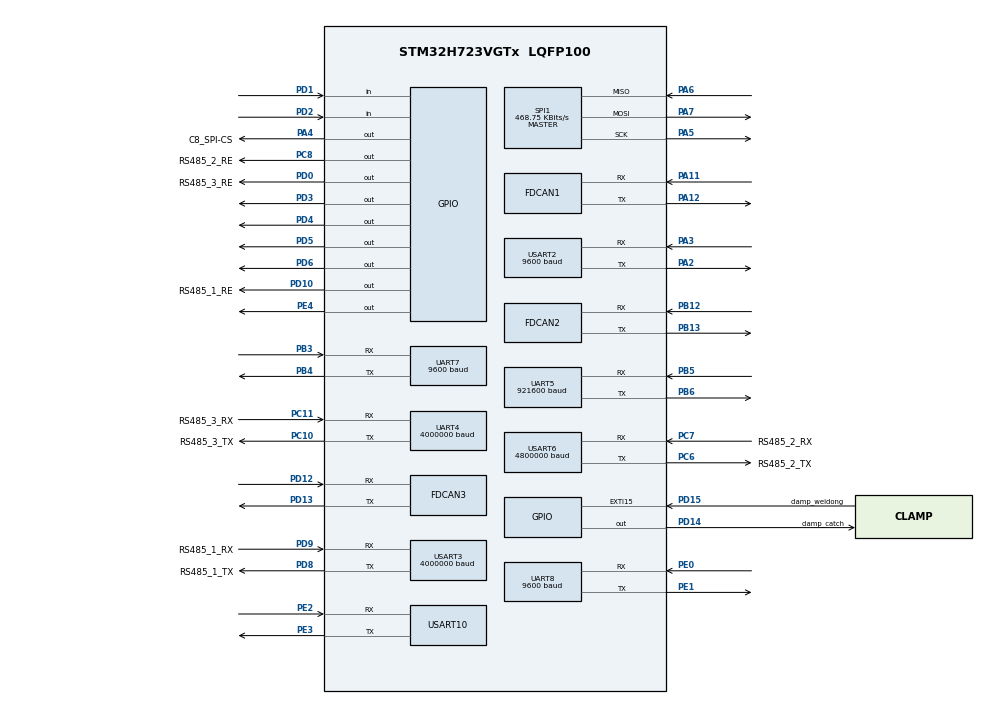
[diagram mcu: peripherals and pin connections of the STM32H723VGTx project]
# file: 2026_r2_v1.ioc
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CORTEX_M7.default_mode_Activation=1
Dma.Request0=UART5_RX
Dma.Request1=UART5_TX
Dma.Request10=USART10_RX
Dma.Request11=USART10_TX
Dma.Request12=UART8_RX
Dma.Request13=UART8_TX
Dma.Request14=USART2_TX
Dma.Request15=USART2_RX
Dma.Request2=USART3_TX
Dma.Request3=USART3_RX
Dma.Request4=USART6_TX
Dma.Request5=USART6_RX
Dma.Request6=UART4_TX
Dma.Request7=UART4_RX
Dma.Request8=UART7_TX
Dma.Request9=UART7_RX
Dma.UART4_RX.7.Direction=DMA_PERIPH_TO_MEMORY
Dma.UART4_RX.7.EventEnable=DISABLE
Dma.UART4_RX.7.FIFOMode=DMA_FIFOMODE_DISABLE
Dma.UART4_RX.7.Instance=DMA1_Stream5
Dma.UART4_RX.7.MemDataAlignment=DMA_MDATAALIGN_BYTE
Dma.UART4_RX.7.MemInc=DMA_MINC_ENABLE
Dma.UART4_RX.7.Mode=DMA_NORMAL
Dma.UART4_RX.7.PeriphDataAlignment=DMA_PDATAALIGN_BYTE
Dma.UART4_RX.7.PeriphInc=DMA_PINC_DISABLE
Dma.UART4_RX.7.Polarity=HAL_DMAMUX_REQ_GEN_RISING
Dma.UART4_RX.7.Priority=DMA_PRIORITY_LOW
Dma.UART4_RX.7.RequestNumber=1
Dma.UART4_RX.7.SignalID=NONE
Dma.UART4_RX.7.SyncEnable=DISABLE
Dma.UART4_RX.7.SyncPolarity=HAL_DMAMUX_SYNC_NO_EVENT
Dma.UART4_RX.7.SyncRequestNumber=1
Dma.UART4_RX.7.SyncSignalID=NONE
Dma.UART4_TX.6.Direction=DMA_MEMORY_TO_PERIPH
Dma.UART4_TX.6.EventEnable=DISABLE
Dma.UART4_TX.6.FIFOMode=DMA_FIFOMODE_DISABLE
Dma.UART4_TX.6.Instance=DMA1_Stream4
Dma.UART4_TX.6.MemDataAlignment=DMA_MDATAALIGN_BYTE
Dma.UART4_TX.6.MemInc=DMA_MINC_ENABLE
Dma.UART4_TX.6.Mode=DMA_NORMAL
Dma.UART4_TX.6.PeriphDataAlignment=DMA_PDATAALIGN_BYTE
Dma.UART4_TX.6.PeriphInc=DMA_PINC_DISABLE
Dma.UART4_TX.6.Polarity=HAL_DMAMUX_REQ_GEN_RISING
Dma.UART4_TX.6.Priority=DMA_PRIORITY_LOW
Dma.UART4_TX.6.RequestNumber=1
Dma.UART4_TX.6.SignalID=NONE
Dma.UART4_TX.6.SyncEnable=DISABLE
Dma.UART4_TX.6.SyncPolarity=HAL_DMAMUX_SYNC_NO_EVENT
Dma.UART4_TX.6.SyncRequestNumber=1
Dma.UART4_TX.6.SyncSignalID=NONE
Dma.UART5_RX.0.Direction=DMA_PERIPH_TO_MEMORY
Dma.UART5_RX.0.EventEnable=DISABLE
Dma.UART5_RX.0.FIFOMode=DMA_FIFOMODE_DISABLE
Dma.UART5_RX.0.Instance=DMA2_Stream2
Dma.UART5_RX.0.MemDataAlignment=DMA_MDATAALIGN_BYTE
Dma.UART5_RX.0.MemInc=DMA_MINC_ENABLE
Dma.UART5_RX.0.Mode=DMA_NORMAL
Dma.UART5_RX.0.PeriphDataAlignment=DMA_PDATAALIGN_BYTE
Dma.UART5_RX.0.PeriphInc=DMA_PINC_DISABLE
Dma.UART5_RX.0.Polarity=HAL_DMAMUX_REQ_GEN_RISING
Dma.UART5_RX.0.Priority=DMA_PRIORITY_LOW
Dma.UART5_RX.0.RequestNumber=1
Dma.UART5_RX.0.SignalID=NONE
Dma.UART5_RX.0.SyncEnable=DISABLE
Dma.UART5_RX.0.SyncPolarity=HAL_DMAMUX_SYNC_NO_EVENT
Dma.UART5_RX.0.SyncRequestNumber=1
Dma.UART5_RX.0.SyncSignalID=NONE
Dma.UART5_TX.1.Direction=DMA_MEMORY_TO_PERIPH
Dma.UART5_TX.1.EventEnable=DISABLE
Dma.UART5_TX.1.FIFOMode=DMA_FIFOMODE_DISABLE
Dma.UART5_TX.1.Instance=DMA2_Stream3
Dma.UART5_TX.1.MemDataAlignment=DMA_MDATAALIGN_BYTE
Dma.UART5_TX.1.MemInc=DMA_MINC_ENABLE
Dma.UART5_TX.1.Mode=DMA_NORMAL
Dma.UART5_TX.1.PeriphDataAlignment=DMA_PDATAALIGN_BYTE
Dma.UART5_TX.1.PeriphInc=DMA_PINC_DISABLE
Dma.UART5_TX.1.Polarity=HAL_DMAMUX_REQ_GEN_RISING
Dma.UART5_TX.1.Priority=DMA_PRIORITY_LOW
Dma.UART5_TX.1.RequestNumber=1
Dma.UART5_TX.1.SignalID=NONE
Dma.UART5_TX.1.SyncEnable=DISABLE
Dma.UART5_TX.1.SyncPolarity=HAL_DMAMUX_SYNC_NO_EVENT
Dma.UART5_TX.1.SyncRequestNumber=1
Dma.UART5_TX.1.SyncSignalID=NONE
Dma.UART7_RX.9.Direction=DMA_PERIPH_TO_MEMORY
Dma.UART7_RX.9.EventEnable=DISABLE
Dma.UART7_RX.9.FIFOMode=DMA_FIFOMODE_DISABLE
Dma.UART7_RX.9.Instance=DMA1_Stream7
Dma.UART7_RX.9.MemDataAlignment=DMA_MDATAALIGN_BYTE
Dma.UART7_RX.9.MemInc=DMA_MINC_ENABLE
Dma.UART7_RX.9.Mode=DMA_NORMAL
Dma.UART7_RX.9.PeriphDataAlignment=DMA_PDATAALIGN_BYTE
Dma.UART7_RX.9.PeriphInc=DMA_PINC_DISABLE
Dma.UART7_RX.9.Polarity=HAL_DMAMUX_REQ_GEN_RISING
Dma.UART7_RX.9.Priority=DMA_PRIORITY_LOW
Dma.UART7_RX.9.RequestNumber=1
Dma.UART7_RX.9.SignalID=NONE
Dma.UART7_RX.9.SyncEnable=DISABLE
Dma.UART7_RX.9.SyncPolarity=HAL_DMAMUX_SYNC_NO_EVENT
Dma.UART7_RX.9.SyncRequestNumber=1
Dma.UART7_RX.9.SyncSignalID=NONE
Dma.UART7_TX.8.Direction=DMA_MEMORY_TO_PERIPH
Dma.UART7_TX.8.EventEnable=DISABLE
Dma.UART7_TX.8.FIFOMode=DMA_FIFOMODE_DISABLE
Dma.UART7_TX.8.Instance=DMA1_Stream6
Dma.UART7_TX.8.MemDataAlignment=DMA_MDATAALIGN_BYTE
Dma.UART7_TX.8.MemInc=DMA_MINC_ENABLE
Dma.UART7_TX.8.Mode=DMA_NORMAL
Dma.UART7_TX.8.PeriphDataAlignment=DMA_PDATAALIGN_BYTE
Dma.UART7_TX.8.PeriphInc=DMA_PINC_DISABLE
Dma.UART7_TX.8.Polarity=HAL_DMAMUX_REQ_GEN_RISING
Dma.UART7_TX.8.Priority=DMA_PRIORITY_LOW
Dma.UART7_TX.8.RequestNumber=1
Dma.UART7_TX.8.SignalID=NONE
Dma.UART7_TX.8.SyncEnable=DISABLE
Dma.UART7_TX.8.SyncPolarity=HAL_DMAMUX_SYNC_NO_EVENT
Dma.UART7_TX.8.SyncRequestNumber=1
Dma.UART7_TX.8.SyncSignalID=NONE
Dma.UART8_RX.12.Direction=DMA_PERIPH_TO_MEMORY
Dma.UART8_RX.12.EventEnable=DISABLE
Dma.UART8_RX.12.FIFOMode=DMA_FIFOMODE_DISABLE
Dma.UART8_RX.12.Instance=DMA2_Stream4
Dma.UART8_RX.12.MemDataAlignment=DMA_MDATAALIGN_BYTE
Dma.UART8_RX.12.MemInc=DMA_MINC_ENABLE
Dma.UART8_RX.12.Mode=DMA_NORMAL
Dma.UART8_RX.12.PeriphDataAlignment=DMA_PDATAALIGN_BYTE
Dma.UART8_RX.12.PeriphInc=DMA_PINC_DISABLE
Dma.UART8_RX.12.Polarity=HAL_DMAMUX_REQ_GEN_RISING
Dma.UART8_RX.12.Priority=DMA_PRIORITY_LOW
Dma.UART8_RX.12.RequestNumber=1
Dma.UART8_RX.12.SignalID=NONE
Dma.UART8_RX.12.SyncEnable=DISABLE
Dma.UART8_RX.12.SyncPolarity=HAL_DMAMUX_SYNC_NO_EVENT
Dma.UART8_RX.12.SyncRequestNumber=1
Dma.UART8_RX.12.SyncSignalID=NONE
Dma.UART8_TX.13.Direction=DMA_MEMORY_TO_PERIPH
Dma.UART8_TX.13.EventEnable=DISABLE
Dma.UART8_TX.13.FIFOMode=DMA_FIFOMODE_DISABLE
Dma.UART8_TX.13.Instance=DMA2_Stream5
Dma.UART8_TX.13.MemDataAlignment=DMA_MDATAALIGN_BYTE
Dma.UART8_TX.13.MemInc=DMA_MINC_ENABLE
Dma.UART8_TX.13.Mode=DMA_NORMAL
Dma.UART8_TX.13.PeriphDataAlignment=DMA_PDATAALIGN_BYTE
Dma.UART8_TX.13.PeriphInc=DMA_PINC_DISABLE
Dma.UART8_TX.13.Polarity=HAL_DMAMUX_REQ_GEN_RISING
Dma.UART8_TX.13.Priority=DMA_PRIORITY_LOW
Dma.UART8_TX.13.RequestNumber=1
Dma.UART8_TX.13.SignalID=NONE
Dma.UART8_TX.13.SyncEnable=DISABLE
Dma.UART8_TX.13.SyncPolarity=HAL_DMAMUX_SYNC_NO_EVENT
Dma.UART8_TX.13.SyncRequestNumber=1
Dma.UART8_TX.13.SyncSignalID=NONE
Dma.USART10_RX.10.Direction=DMA_PERIPH_TO_MEMORY
Dma.USART10_RX.10.EventEnable=DISABLE
Dma.USART10_RX.10.FIFOMode=DMA_FIFOMODE_DISABLE
Dma.USART10_RX.10.Instance=DMA2_Stream0
Dma.USART10_RX.10.MemDataAlignment=DMA_MDATAALIGN_BYTE
Dma.USART10_RX.10.MemInc=DMA_MINC_ENABLE
Dma.USART10_RX.10.Mode=DMA_NORMAL
Dma.USART10_RX.10.PeriphDataAlignment=DMA_PDATAALIGN_BYTE
Dma.USART10_RX.10.PeriphInc=DMA_PINC_DISABLE
Dma.USART10_RX.10.Polarity=HAL_DMAMUX_REQ_GEN_RISING
Dma.USART10_RX.10.Priority=DMA_PRIORITY_LOW
Dma.USART10_RX.10.RequestNumber=1
Dma.USART10_RX.10.SignalID=NONE
Dma.USART10_RX.10.SyncEnable=DISABLE
Dma.USART10_RX.10.SyncPolarity=HAL_DMAMUX_SYNC_NO_EVENT
Dma.USART10_RX.10.SyncRequestNumber=1
Dma.USART10_RX.10.SyncSignalID=NONE
Dma.USART10_TX.11.Direction=DMA_MEMORY_TO_PERIPH
Dma.USART10_TX.11.EventEnable=DISABLE
Dma.USART10_TX.11.FIFOMode=DMA_FIFOMODE_DISABLE
Dma.USART10_TX.11.Instance=DMA2_Stream1
Dma.USART10_TX.11.MemDataAlignment=DMA_MDATAALIGN_BYTE
Dma.USART10_TX.11.MemInc=DMA_MINC_ENABLE
Dma.USART10_TX.11.Mode=DMA_NORMAL
Dma.USART10_TX.11.PeriphDataAlignment=DMA_PDATAALIGN_BYTE
Dma.USART10_TX.11.PeriphInc=DMA_PINC_DISABLE
Dma.USART10_TX.11.Polarity=HAL_DMAMUX_REQ_GEN_RISING
Dma.USART10_TX.11.Priority=DMA_PRIORITY_LOW
Dma.USART10_TX.11.RequestNumber=1
Dma.USART10_TX.11.SignalID=NONE
Dma.USART10_TX.11.SyncEnable=DISABLE
Dma.USART10_TX.11.SyncPolarity=HAL_DMAMUX_SYNC_NO_EVENT
Dma.USART10_TX.11.SyncRequestNumber=1
Dma.USART10_TX.11.SyncSignalID=NONE
Dma.USART2_RX.15.Direction=DMA_PERIPH_TO_MEMORY
Dma.USART2_RX.15.EventEnable=DISABLE
Dma.USART2_RX.15.FIFOMode=DMA_FIFOMODE_DISABLE
Dma.USART2_RX.15.Instance=DMA2_Stream7
Dma.USART2_RX.15.MemDataAlignment=DMA_MDATAALIGN_BYTE
Dma.USART2_RX.15.MemInc=DMA_MINC_ENABLE
Dma.USART2_RX.15.Mode=DMA_NORMAL
Dma.USART2_RX.15.PeriphDataAlignment=DMA_PDATAALIGN_BYTE
Dma.USART2_RX.15.PeriphInc=DMA_PINC_DISABLE
Dma.USART2_RX.15.Polarity=HAL_DMAMUX_REQ_GEN_RISING
Dma.USART2_RX.15.Priority=DMA_PRIORITY_LOW
Dma.USART2_RX.15.RequestNumber=1
Dma.USART2_RX.15.SignalID=NONE
Dma.USART2_RX.15.SyncEnable=DISABLE
Dma.USART2_RX.15.SyncPolarity=HAL_DMAMUX_SYNC_NO_EVENT
Dma.USART2_RX.15.SyncRequestNumber=1
Dma.USART2_RX.15.SyncSignalID=NONE
Dma.USART2_TX.14.Direction=DMA_MEMORY_TO_PERIPH
Dma.USART2_TX.14.EventEnable=DISABLE
Dma.USART2_TX.14.FIFOMode=DMA_FIFOMODE_DISABLE
Dma.USART2_TX.14.Instance=DMA2_Stream6
Dma.USART2_TX.14.MemDataAlignment=DMA_MDATAALIGN_BYTE
Dma.USART2_TX.14.MemInc=DMA_MINC_ENABLE
Dma.USART2_TX.14.Mode=DMA_NORMAL
Dma.USART2_TX.14.PeriphDataAlignment=DMA_PDATAALIGN_BYTE
Dma.USART2_TX.14.PeriphInc=DMA_PINC_DISABLE
Dma.USART2_TX.14.Polarity=HAL_DMAMUX_REQ_GEN_RISING
Dma.USART2_TX.14.Priority=DMA_PRIORITY_LOW
Dma.USART2_TX.14.RequestNumber=1
Dma.USART2_TX.14.SignalID=NONE
Dma.USART2_TX.14.SyncEnable=DISABLE
Dma.USART2_TX.14.SyncPolarity=HAL_DMAMUX_SYNC_NO_EVENT
Dma.USART2_TX.14.SyncRequestNumber=1
Dma.USART2_TX.14.SyncSignalID=NONE
Dma.USART3_RX.3.Direction=DMA_PERIPH_TO_MEMORY
Dma.USART3_RX.3.EventEnable=DISABLE
Dma.USART3_RX.3.FIFOMode=DMA_FIFOMODE_DISABLE
Dma.USART3_RX.3.Instance=DMA1_Stream1
Dma.USART3_RX.3.MemDataAlignment=DMA_MDATAALIGN_BYTE
Dma.USART3_RX.3.MemInc=DMA_MINC_ENABLE
Dma.USART3_RX.3.Mode=DMA_NORMAL
Dma.USART3_RX.3.PeriphDataAlignment=DMA_PDATAALIGN_BYTE
Dma.USART3_RX.3.PeriphInc=DMA_PINC_DISABLE
Dma.USART3_RX.3.Polarity=HAL_DMAMUX_REQ_GEN_RISING
Dma.USART3_RX.3.Priority=DMA_PRIORITY_LOW
Dma.USART3_RX.3.RequestNumber=1
Dma.USART3_RX.3.SignalID=NONE
Dma.USART3_RX.3.SyncEnable=DISABLE
Dma.USART3_RX.3.SyncPolarity=HAL_DMAMUX_SYNC_NO_EVENT
Dma.USART3_RX.3.SyncRequestNumber=1
Dma.USART3_RX.3.SyncSignalID=NONE
Dma.USART3_TX.2.Direction=DMA_MEMORY_TO_PERIPH
Dma.USART3_TX.2.EventEnable=DISABLE
Dma.USART3_TX.2.FIFOMode=DMA_FIFOMODE_DISABLE
Dma.USART3_TX.2.Instance=DMA1_Stream0
Dma.USART3_TX.2.MemDataAlignment=DMA_MDATAALIGN_BYTE
Dma.USART3_TX.2.MemInc=DMA_MINC_ENABLE
Dma.USART3_TX.2.Mode=DMA_NORMAL
Dma.USART3_TX.2.PeriphDataAlignment=DMA_PDATAALIGN_BYTE
Dma.USART3_TX.2.PeriphInc=DMA_PINC_DISABLE
Dma.USART3_TX.2.Polarity=HAL_DMAMUX_REQ_GEN_RISING
Dma.USART3_TX.2.Priority=DMA_PRIORITY_LOW
Dma.USART3_TX.2.RequestNumber=1
Dma.USART3_TX.2.SignalID=NONE
Dma.USART3_TX.2.SyncEnable=DISABLE
Dma.USART3_TX.2.SyncPolarity=HAL_DMAMUX_SYNC_NO_EVENT
Dma.USART3_TX.2.SyncRequestNumber=1
Dma.USART3_TX.2.SyncSignalID=NONE
Dma.USART6_RX.5.Direction=DMA_PERIPH_TO_MEMORY
Dma.USART6_RX.5.EventEnable=DISABLE
Dma.USART6_RX.5.FIFOMode=DMA_FIFOMODE_DISABLE
Dma.USART6_RX.5.Instance=DMA1_Stream3
Dma.USART6_RX.5.MemDataAlignment=DMA_MDATAALIGN_BYTE
Dma.USART6_RX.5.MemInc=DMA_MINC_ENABLE
Dma.USART6_RX.5.Mode=DMA_NORMAL
Dma.USART6_RX.5.PeriphDataAlignment=DMA_PDATAALIGN_BYTE
Dma.USART6_RX.5.PeriphInc=DMA_PINC_DISABLE
Dma.USART6_RX.5.Polarity=HAL_DMAMUX_REQ_GEN_RISING
Dma.USART6_RX.5.Priority=DMA_PRIORITY_LOW
Dma.USART6_RX.5.RequestNumber=1
Dma.USART6_RX.5.SignalID=NONE
Dma.USART6_RX.5.SyncEnable=DISABLE
Dma.USART6_RX.5.SyncPolarity=HAL_DMAMUX_SYNC_NO_EVENT
Dma.USART6_RX.5.SyncRequestNumber=1
Dma.USART6_RX.5.SyncSignalID=NONE
Dma.USART6_TX.4.Direction=DMA_MEMORY_TO_PERIPH
Dma.USART6_TX.4.EventEnable=DISABLE
Dma.USART6_TX.4.FIFOMode=DMA_FIFOMODE_DISABLE
Dma.USART6_TX.4.Instance=DMA1_Stream2
Dma.USART6_TX.4.MemDataAlignment=DMA_MDATAALIGN_BYTE
Dma.USART6_TX.4.MemInc=DMA_MINC_ENABLE
Dma.USART6_TX.4.Mode=DMA_NORMAL
Dma.USART6_TX.4.PeriphDataAlignment=DMA_PDATAALIGN_BYTE
Dma.USART6_TX.4.PeriphInc=DMA_PINC_DISABLE
Dma.USART6_TX.4.Polarity=HAL_DMAMUX_REQ_GEN_RISING
Dma.USART6_TX.4.Priority=DMA_PRIORITY_LOW
Dma.USART6_TX.4.RequestNumber=1
Dma.USART6_TX.4.SignalID=NONE
Dma.USART6_TX.4.SyncEnable=DISABLE
Dma.USART6_TX.4.SyncPolarity=HAL_DMAMUX_SYNC_NO_EVENT
Dma.USART6_TX.4.SyncRequestNumber=1
Dma.USART6_TX.4.SyncSignalID=NONE
FDCAN1.CalculateBaudRateNominal=1000000
FDCAN1.CalculateTimeBitNominal=1000
FDCAN1.CalculateTimeQuantumNominal=25.0
FDCAN1.DataPrescaler=3
FDCAN1.DataSyncJumpWidth=10
FDCAN1.DataTimeSeg1=29
FDCAN1.DataTimeSeg2=10
FDCAN1.NominalPrescaler=3
FDCAN1.NominalSyncJumpWidth=10
FDCAN1.NominalTimeSeg1=29
FDCAN1.NominalTimeSeg2=10
FDCAN1.RxFifo0ElmtsNbr=8
FDCAN1.StdFiltersNbr=1
FDCAN1.TxFifoQueueElmtsNbr=8
FDCAN2.CalculateBaudRateNominal=1000000
FDCAN2.CalculateTimeBitNominal=1000
FDCAN2.CalculateTimeQuantumNominal=25.0
FDCAN2.DataPrescaler=3
FDCAN2.DataSyncJumpWidth=10
FDCAN2.DataTimeSeg1=29
FDCAN2.DataTimeSeg2=10
FDCAN2.FrameFormat=FDCAN_FRAME_CLASSIC
FDCAN2.MessageRAMOffset=512
FDCAN2.NominalPrescaler=3
FDCAN2.NominalSyncJumpWidth=10
FDCAN2.NominalTimeSeg1=29
FDCAN2.NominalTimeSeg2=10
FDCAN2.RxFifo0ElmtsNbr=8
FDCAN2.StdFiltersNbr=1
FDCAN2.TxFifoQueueElmtsNbr=8
FDCAN3.CalculateBaudRateNominal=1000000
FDCAN3.CalculateTimeBitNominal=1000
FDCAN3.CalculateTimeQuantumNominal=25.0
FDCAN3.DataPrescaler=3
FDCAN3.DataSyncJumpWidth=10
FDCAN3.DataTimeSeg1=29
FDCAN3.DataTimeSeg2=10
FDCAN3.MessageRAMOffset=1024
FDCAN3.NominalPrescaler=3
FDCAN3.NominalSyncJumpWidth=10
FDCAN3.NominalTimeSeg1=29
FDCAN3.NominalTimeSeg2=10
FDCAN3.RxFifo0ElmtsNbr=8
FDCAN3.StdFiltersNbr=1
FDCAN3.TxFifoQueueElmtsNbr=8
FREERTOS.BinarySemaphores01=bisem_m8010,Static,bisem_m8010ControlBlock,Available
FREERTOS.Tasks01=defaultTask,-3,256,StartDefaultTask,Default,NULL,Dynamic,NULL,NULL;roboticarm_task,-1,256,entry_robotic_arm,Default,NULL,Dynamic,NULL,NULL;chassis_task,-1,256,entry_chassis,Default,NULL,Dynamic,NULL,NULL;clamp_task,-1,256,entry_clamp,Default,NULL,Dynamic,NULL,NULL;cmd_task,0,1024,entry_cmd_task,Default,NULL,Dynamic,NULL,NULL;m8010_task,0,128,entry_m8010_task,Default,NULL,Dynamic,NULL,NULL;a1_task,0,128,entry_a1_task,Default,NULL,Dynamic,NULL,NULL
FREERTOS.configTOTAL_HEAP_SIZE=32768
Mcu.Family=STM32H7
Mcu.Name=STM32H723VGTx
Mcu.Package=LQFP100
NVIC.DMA1_Stream0_IRQn=true\:5\:0\:false\:false\:true\:true\:false\:true\:true
NVIC.DMA1_Stream1_IRQn=true\:5\:0\:false\:false\:true\:true\:false\:true\:true
NVIC.DMA1_Stream2_IRQn=true\:5\:0\:false\:false\:true\:true\:false\:true\:true
NVIC.DMA1_Stream3_IRQn=true\:5\:0\:false\:false\:true\:true\:false\:true\:true
NVIC.DMA1_Stream4_IRQn=true\:5\:0\:false\:false\:true\:true\:false\:true\:true
NVIC.DMA1_Stream5_IRQn=true\:5\:0\:false\:false\:true\:true\:false\:true\:true
NVIC.DMA1_Stream6_IRQn=true\:5\:0\:false\:false\:true\:true\:false\:true\:true
NVIC.DMA1_Stream7_IRQn=true\:5\:0\:false\:false\:true\:true\:false\:true\:true
NVIC.DMA2_Stream0_IRQn=true\:5\:0\:false\:false\:true\:true\:false\:true\:true
NVIC.DMA2_Stream1_IRQn=true\:5\:0\:false\:false\:true\:true\:false\:true\:true
NVIC.DMA2_Stream2_IRQn=true\:5\:0\:false\:false\:true\:true\:false\:true\:true
NVIC.DMA2_Stream3_IRQn=true\:5\:0\:false\:false\:true\:true\:false\:true\:true
NVIC.DMA2_Stream4_IRQn=true\:5\:0\:false\:false\:true\:true\:false\:true\:true
NVIC.DMA2_Stream5_IRQn=true\:5\:0\:false\:false\:true\:true\:false\:true\:true
NVIC.DMA2_Stream6_IRQn=true\:5\:0\:false\:false\:true\:true\:false\:true\:true
NVIC.DMA2_Stream7_IRQn=true\:5\:0\:false\:false\:true\:true\:false\:true\:true
NVIC.EXTI15_10_IRQn=true\:5\:0\:false\:false\:true\:true\:true\:true\:true
NVIC.FDCAN1_IT0_IRQn=true\:5\:0\:false\:false\:true\:true\:true\:true\:true
NVIC.FDCAN1_IT1_IRQn=true\:5\:0\:false\:false\:true\:true\:true\:true\:true
NVIC.FDCAN2_IT0_IRQn=true\:5\:0\:false\:false\:true\:true\:true\:true\:true
NVIC.FDCAN2_IT1_IRQn=true\:5\:0\:false\:false\:true\:true\:true\:true\:true
NVIC.FDCAN3_IT0_IRQn=true\:5\:0\:false\:false\:true\:true\:true\:true\:true
NVIC.FDCAN3_IT1_IRQn=true\:5\:0\:false\:false\:true\:true\:true\:true\:true
NVIC.PriorityGroup=NVIC_PRIORITYGROUP_4
NVIC.TIM1_UP_IRQn=true\:15\:0\:false\:false\:true\:false\:false\:true\:true
NVIC.TIM2_IRQn=true\:5\:0\:false\:false\:true\:true\:true\:true\:true
NVIC.TIM6_DAC_IRQn=true\:5\:0\:false\:false\:true\:true\:true\:true\:true
NVIC.TIM7_IRQn=true\:5\:0\:false\:false\:true\:true\:true\:true\:true
NVIC.TimeBase=TIM1_UP_IRQn
NVIC.TimeBaseIP=TIM1
NVIC.UART4_IRQn=true\:5\:0\:false\:false\:true\:true\:true\:true\:true
NVIC.UART5_IRQn=true\:5\:0\:false\:false\:true\:true\:true\:true\:true
NVIC.UART7_IRQn=true\:5\:0\:false\:false\:true\:true\:true\:true\:true
NVIC.UART8_IRQn=true\:5\:0\:false\:false\:true\:true\:true\:true\:true
NVIC.USART10_IRQn=true\:5\:0\:false\:false\:true\:true\:true\:true\:true
NVIC.USART2_IRQn=true\:5\:0\:false\:false\:true\:true\:true\:true\:true
NVIC.USART3_IRQn=true\:5\:0\:false\:false\:true\:true\:true\:true\:true
NVIC.USART6_IRQn=true\:5\:0\:false\:false\:true\:true\:true\:true\:true
PA11.Mode=FDCAN_Activate
PA11.Signal=FDCAN1_RX
PA12.Mode=FDCAN_Activate
PA12.Signal=FDCAN1_TX
PA2.Mode=Asynchronous
PA2.Signal=USART2_TX
PA3.Mode=Asynchronous
PA3.Signal=USART2_RX
PA4.GPIO_Label=C8_SPI-CS
PA4.GPIO_Speed=GPIO_SPEED_FREQ_HIGH
PA4.PinState=GPIO_PIN_SET
PA4.Signal=GPIO_Output
PA5.GPIO_Speed=GPIO_SPEED_FREQ_HIGH
PA5.Mode=Full_Duplex_Master
PA5.Signal=SPI1_SCK
PA6.GPIO_Speed=GPIO_SPEED_FREQ_HIGH
PA6.Mode=Full_Duplex_Master
PA6.Signal=SPI1_MISO
PA7.GPIO_Speed=GPIO_SPEED_FREQ_HIGH
PA7.Mode=Full_Duplex_Master
PA7.Signal=SPI1_MOSI
PB12.Mode=FDCAN_Activate
PB12.Signal=FDCAN2_RX
PB13.Mode=FDCAN_Activate
PB13.Signal=FDCAN2_TX
PB3(JTDO/TRACESWO).Mode=Asynchronous
PB3(JTDO/TRACESWO).Signal=UART7_RX
PB4(NJTRST).Mode=Asynchronous
PB4(NJTRST).Signal=UART7_TX
PB5.Mode=Asynchronous
PB5.Signal=UART5_RX
PB6.Mode=Asynchronous
PB6.Signal=UART5_TX
PC10.GPIO_Label=RS485_3_TX
PC10.Mode=Asynchronous
PC10.Signal=UART4_TX
PC11.GPIO_Label=RS485_3_RX
PC11.Mode=Asynchronous
PC11.Signal=UART4_RX
PC14-OSC32_IN.Mode=LSE-External-Oscillator
PC14-OSC32_IN.Signal=RCC_OSC32_IN
PC15-OSC32_OUT.Mode=LSE-External-Oscillator
PC15-OSC32_OUT.Signal=RCC_OSC32_OUT
PC6.GPIO_Label=RS485_2_TX
PC6.Mode=Asynchronous
PC6.Signal=USART6_TX
PC7.GPIO_Label=RS485_2_RX
PC7.Mode=Asynchronous
PC7.Signal=USART6_RX
PC8.GPIO_Label=RS485_2_RE
PC8.GPIO_Speed=GPIO_SPEED_FREQ_HIGH
PC8.Signal=GPIO_Output
PD0.GPIO_Label=RS485_3_RE
PD0.GPIO_Speed=GPIO_SPEED_FREQ_HIGH
PD0.Signal=GPIO_Output
PD1.GPIO_PuPd=GPIO_PULLUP
PD1.Signal=GPIO_Input
PD10.GPIO_Label=RS485_1_RE
PD10.GPIO_Speed=GPIO_SPEED_FREQ_HIGH
PD10.Signal=GPIO_Output
PD12.Mode=FDCAN_Activate
PD12.Signal=FDCAN3_RX
PD13.Mode=FDCAN_Activate
PD13.Signal=FDCAN3_TX
PD14.GPIO_Label=clamp_catch
PD14.Signal=GPIO_Output
PD15.GPIO_Label=clamp_weidong
PD15.GPIO_ModeDefaultEXTI=GPIO_MODE_IT_RISING_FALLING
PD15.GPIO_PuPd=GPIO_PULLUP
PD15.Signal=GPXTI15
PD2.GPIO_PuPd=GPIO_PULLUP
PD2.Signal=GPIO_Input
PD3.Signal=GPIO_Output
PD4.Signal=GPIO_Output
PD5.Signal=GPIO_Output
PD6.Signal=GPIO_Output
PD8.GPIO_Label=RS485_1_TX
PD8.Mode=Asynchronous
PD8.Signal=USART3_TX
PD9.GPIO_Label=RS485_1_RX
PD9.Mode=Asynchronous
PD9.Signal=USART3_RX
PE0.Mode=Asynchronous
PE0.Signal=UART8_RX
PE1.Mode=Asynchronous
PE1.Signal=UART8_TX
PE2.Mode=Asynchronous
PE2.Signal=USART10_RX
PE3.Mode=Asynchronous
PE3.Signal=USART10_TX
PE4.Signal=GPIO_Output
PH0-OSC_IN.Mode=HSE-External-Oscillator
PH0-OSC_IN.Signal=RCC_OSC_IN
PH1-OSC_OUT.Mode=HSE-External-Oscillator
PH1-OSC_OUT.Signal=RCC_OSC_OUT
ProjectManager.HeapSize=0x800
ProjectManager.StackSize=0x2000
ProjectManager.TargetToolchain=MDK-ARM V5.32
RCC.ADCFreq_Value=129000000
RCC.APB1Freq_Value=120000000
RCC.APB2Freq_Value=120000000
RCC.APB3Freq_Value=120000000
RCC.APB4Freq_Value=120000000
RCC.CortexFreq_Value=480000000
RCC.D1PPRE=RCC_APB3_DIV2
RCC.D2PPRE1=RCC_APB1_DIV2
RCC.D2PPRE2=RCC_APB2_DIV2
RCC.D3PPRE=RCC_APB4_DIV2
RCC.DIVM1=4
RCC.DIVN1=30
RCC.DIVP1=1
RCC.DIVQ1=4
RCC.HCLKFreq_Value=240000000
RCC.HPRE=RCC_HCLK_DIV2
RCC.PLL2FRACN=0
RCC.PLL3FRACN=0
RCC.PLLFRACN=0
RCC.SYSCLKFreq_VALUE=480000000
RCC.SYSCLKSource=RCC_SYSCLKSOURCE_PLLCLK
RCC.USBFreq_Value=120000000
SPI1.BaudRatePrescaler=SPI_BAUDRATEPRESCALER_256
SPI1.CalculateBaudRate=468.75 KBits/s
SPI1.DataSize=SPI_DATASIZE_8BIT
SPI1.Direction=SPI_DIRECTION_2LINES
SPI1.Mode=SPI_MODE_MASTER
SPI1.VirtualType=VM_MASTER
TIM2.Period=1000-1
TIM2.Prescaler=240-1
TIM6.Period=500-1
TIM6.Prescaler=240-1
TIM7.Period=1000-1
TIM7.Prescaler=240-1
UART4.BaudRate=4000000
UART5.BaudRate=921600
UART5.Parity=PARITY_NONE
UART5.RxPinLevelInvertParam=UART_ADVFEATURE_RXINV_DISABLE
UART5.StopBits=UART_STOPBITS_1
UART5.TxPinLevelInvertParam=UART_ADVFEATURE_TXINV_DISABLE
UART5.WordLength=WORDLENGTH_8B
UART7.BaudRate=9600
UART8.BaudRate=9600
USART10.VirtualMode=VM_ASYNC
USART2.BaudRate=9600
USART2.VirtualMode-Asynchronous=VM_ASYNC
USART3.BaudRate=4000000
USART3.VirtualMode-Asynchronous=VM_ASYNC
USART6.BaudRate=4800000
USART6.VirtualMode=VM_ASYNC
VP_FREERTOS_VS_CMSIS_V1.Mode=CMSIS_V1
VP_MEMORYMAP_VS_MEMORYMAP.Mode=CurAppReg
VP_SYS_VS_tim1.Mode=TIM1
VP_TIM2_VS_ClockSourceINT.Mode=Internal
VP_TIM6_VS_ClockSourceINT.Mode=Enable_Timer
VP_TIM7_VS_ClockSourceINT.Mode=Enable_Timer
board=custom

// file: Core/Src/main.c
/* USER CODE BEGIN Header */
/**
 ******************************************************************************
 * @file           : main.c
 * @brief          : Main program body
 ******************************************************************************
 * @attention
 *
 * Copyright (c) 2026 STMicroelectronics.
 * All rights reserved.
 *
 * This software is licensed under terms that can be found in the LICENSE file
 * in the root directory of this software component.
 * If no LICENSE file comes with this software, it is provided AS-IS.
 *
 ******************************************************************************
 */
/* USER CODE END Header */
#include "main.h"
#include "cmsis_os.h"
#include "dma.h"
#include "fdcan.h"
#include "spi.h"
#include "tim.h"
#include "usart.h"
#include "gpio.h"

/* USER CODE BEGIN Includes */
#include "own_lib.h"
#include "mycan.h"
#include "myuart.h"
#include "filter.h"
#include "observer.h"
#include "pid.h"
#include "m3508.h"
#include "a1_motor.h"
#include "ht10a.h"
#include "hi14.h"
#include "clamp.h"
#include "go_m8010.h"
#include "BT_customized.h"
#include "camera.h"
#include "H7_F1_spi.h"
//#include "Ana_keyboard.h"
#include "screen.h"
#include "keyboard.h"
/* USER CODE END Includes */

/* USER CODE BEGIN PV */

extern osSemaphoreId bisem_m8010Handle; // ← 新增（v1 中类型名可能是 osSemaphoreId）

// uint8_t timer_a1_flag = 0; // 用于使定时器中对A1电机依次发送的标志位，0-3分别对应4个电机

uint32_t timer_ms = 0; // 定时器计时变量，单位ms

volatile uint8_t a1_send_request = 0; // a1电机发送请求标志位，由定时器中断设置

// uint8_t m3508_send_flag = 0;//用于使定时器中对M3508电机依次发送的标志位
/* USER CODE END PV */

void SystemClock_Config(void);
static void MPU_Config(void);
void MX_FREERTOS_Init(void);

int main(void)
{

  /* MPU Configuration--------------------------------------------------------*/
  MPU_Config();

  /* MCU Configuration--------------------------------------------------------*/

  /* Reset of all peripherals, Initializes the Flash interface and the Systick. */
  HAL_Init();

  /* Configure the system clock */
  SystemClock_Config();

  /* Initialize all configured peripherals */
  MX_GPIO_Init();
  MX_DMA_Init();
  MX_FDCAN1_Init();
  MX_TIM6_Init();
  MX_TIM7_Init();
  MX_FDCAN2_Init();
  MX_FDCAN3_Init();
  MX_TIM2_Init();
  MX_UART5_Init();
  MX_UART4_Init();
  MX_USART3_UART_Init();
  MX_USART6_UART_Init();
  MX_UART7_Init();
  MX_USART10_UART_Init();
  MX_UART8_Init();
  MX_SPI1_Init();
  MX_USART2_UART_Init();
  /* USER CODE BEGIN 2 */

  // H7(SPI1 Master) <-> F103C8T6(SPI1 Slave) 红外状态通信初始化
  // CS 使用 PA4 软件控制，空闲为高电平。
  H7_F1_SPI_Init(&hspi1);
  Screen_InitDisplay();
  // FDCAN初始化，配置过滤器并开启CAN
  FDCan_Start(&FDCAN_Default_FilterConfig_1);

  // uart9-a1
  //  memset(a1_usart9_raw_recv.RX_pData, 0, sizeof(a1_usart9_raw_recv.RX_pData));
  //  HAL_UARTEx_ReceiveToIdle_DMA(&huart9, a1_usart9_raw_recv.RX_pData, RX_LEN1);
  //  __HAL_DMA_DISABLE_IT(&hdma_uart9_rx, DMA_IT_HT);
  // uart8-ht10a
  //  memset(ht10a_buffer, 0, sizeof(ht10a_buffer));
  //  HAL_UARTEx_ReceiveToIdle_DMA(&huart8, ht10a_buffer, sizeof(ht10a_buffer));
  //  __HAL_DMA_DISABLE_IT(&hdma_uart8_rx, DMA_IT_HT);
  // uart6-ht10a-仅调试用，实际不适用
  //  memset(ht10a_buffer, 0, sizeof(ht10a_buffer));
  //  HAL_UARTEx_ReceiveToIdle_DMA(&huart6, ht10a_buffer, sizeof(ht10a_buffer));
  //  __HAL_DMA_DISABLE_IT(&hdma_usart6_rx, DMA_IT_HT);

  // uart1-a1
   memset(a1_usart6_raw_recv.RX_pData, 0, sizeof(a1_usart6_raw_recv.RX_pData));
   HAL_UARTEx_ReceiveToIdle_DMA(&huart6, a1_usart6_raw_recv.RX_pData, RX_LEN1);
   __HAL_DMA_DISABLE_IT(&hdma_usart6_rx, DMA_IT_HT);

  // uart10 - hi14
  memset(dma_rx_buf, 0, sizeof(dma_rx_buf));
  HAL_UARTEx_ReceiveToIdle_DMA(&huart10, dma_rx_buf, sizeof(dma_rx_buf));
  __HAL_DMA_DISABLE_IT(&hdma_usart10_rx, DMA_IT_HT);

  // uart5 - radar
  memset(Rec_Data, 0, sizeof(Rec_Data));
  HAL_UARTEx_ReceiveToIdle_DMA(&huart5, Rec_Data, sizeof(Rec_Data));
  __HAL_DMA_DISABLE_IT(&hdma_uart5_rx, DMA_IT_HT);
  // uart5 - ht10
  // memset(ht10a_buffer, 0, sizeof(ht10a_buffer));
  // HAL_UARTEx_ReceiveToIdle_DMA(&huart5, ht10a_buffer, sizeof(ht10a_buffer));
  // __HAL_DMA_DISABLE_IT(&hdma_uart5_rx, DMA_IT_HT);

  // // uart8 - camera
  // memset(Camera_Rec_Data, 0, sizeof(Camera_Rec_Data));
  // HAL_UARTEx_ReceiveToIdle_DMA(&huart8, Camera_Rec_Data, sizeof(Camera_Rec_Data));
  // __HAL_DMA_DISABLE_IT(&hdma_uart8_rx, DMA_IT_HT);

  // uart8 - keyboard
  memset(keyboard_buffer, 0, sizeof(keyboard_buffer));
  HAL_UARTEx_ReceiveToIdle_DMA(&huart8, keyboard_buffer, sizeof(keyboard_buffer));
  __HAL_DMA_DISABLE_IT(&hdma_uart8_rx, DMA_IT_HT);

  // uart2 - keyboard2
  memset(keyboard_2_buffer, 0, sizeof(keyboard_2_buffer));
  HAL_UARTEx_ReceiveToIdle_DMA(&huart2, keyboard_2_buffer, sizeof(keyboard_2_buffer));
  __HAL_DMA_DISABLE_IT(&hdma_usart2_rx, DMA_IT_HT);

  // 雷达卡尔曼滤波器初始化
  Kalman_Init(&Radar_Kalman_X, 0.0001f, 100.0f, 0.0f, 400.0f);
  Kalman_Init(&Radar_Kalman_Y, 0.0001f, 100.0f, 0.0f, 1400.0f);
  Kalman_Init(&Radar_Kalman_Z, 0.0001f, 100.0f, 0.0f, 140.0f);
  Kalman_Init(&Radar_Kalman_Yaw, 0.0001f, 100.0f, 0.0f, 0.0f);

  // go_m8010电机总线初始化
  m8010_bus_init(&m8010_bus_1, &huart3, &htim6);
  // m8010_bus_init(&m8010_bus_2, &huart6, &htim6);
  m8010_bus_init(&m8010_bus_3, &huart4, &htim6);

  A1_Motor_Parameter_Init(&A1_debug_485_2[0], 0, 10, 0, 0);
  A1_Motor_Parameter_Init(&A1_debug_485_2[1], 1, 10, 0, 0);
  A1_Motor_Parameter_Init(&A1_debug_485_2[2], 2, 10, 0, 0);

  // clamp_position_init(&m3508_fdcan2[1],&m3508_fdcan2[3],&m3508_fdcan2[2]);
  /* USER CODE END 2 */

  /* Call init function for freertos objects (in cmsis_os2.c) */
  MX_FREERTOS_Init();

  /* Start scheduler */
  osKernelStart();

  /* We should never get here as control is now taken by the scheduler */

  /* Infinite loop */
  while (1)
  {

  }
}

void SystemClock_Config(void)
{
  RCC_OscInitTypeDef RCC_OscInitStruct = {0};
  RCC_ClkInitTypeDef RCC_ClkInitStruct = {0};

  /** Supply configuration update enable
  */
  HAL_PWREx_ConfigSupply(PWR_LDO_SUPPLY);

  /** Configure the main internal regulator output voltage
  */
  __HAL_PWR_VOLTAGESCALING_CONFIG(PWR_REGULATOR_VOLTAGE_SCALE0);

  while(!__HAL_PWR_GET_FLAG(PWR_FLAG_VOSRDY)) {}

  /** Initializes the RCC Oscillators according to the specified parameters
  * in the RCC_OscInitTypeDef structure.
  */
  RCC_OscInitStruct.OscillatorType = RCC_OSCILLATORTYPE_HSI;
  RCC_OscInitStruct.HSIState = RCC_HSI_DIV1;
  RCC_OscInitStruct.HSICalibrationValue = 64;
  RCC_OscInitStruct.PLL.PLLState = RCC_PLL_ON;
  RCC_OscInitStruct.PLL.PLLSource = RCC_PLLSOURCE_HSI;
  RCC_OscInitStruct.PLL.PLLM = 4;
  RCC_OscInitStruct.PLL.PLLN = 30;
  RCC_OscInitStruct.PLL.PLLP = 1;
  RCC_OscInitStruct.PLL.PLLQ = 4;
  RCC_OscInitStruct.PLL.PLLR = 2;
  RCC_OscInitStruct.PLL.PLLRGE = RCC_PLL1VCIRANGE_3;
  RCC_OscInitStruct.PLL.PLLVCOSEL = RCC_PLL1VCOWIDE;
  RCC_OscInitStruct.PLL.PLLFRACN = 0;
  if (HAL_RCC_OscConfig(&RCC_OscInitStruct) != HAL_OK)
  {
    Error_Handler();
  }

  /** Initializes the CPU, AHB and APB buses clocks
  */
  RCC_ClkInitStruct.ClockType = RCC_CLOCKTYPE_HCLK|RCC_CLOCKTYPE_SYSCLK
                              |RCC_CLOCKTYPE_PCLK1|RCC_CLOCKTYPE_PCLK2
                              |RCC_CLOCKTYPE_D3PCLK1|RCC_CLOCKTYPE_D1PCLK1;
  RCC_ClkInitStruct.SYSCLKSource = RCC_SYSCLKSOURCE_PLLCLK;
  RCC_ClkInitStruct.SYSCLKDivider = RCC_SYSCLK_DIV1;
  RCC_ClkInitStruct.AHBCLKDivider = RCC_HCLK_DIV2;
  RCC_ClkInitStruct.APB3CLKDivider = RCC_APB3_DIV2;
  RCC_ClkInitStruct.APB1CLKDivider = RCC_APB1_DIV2;
  RCC_ClkInitStruct.APB2CLKDivider = RCC_APB2_DIV2;
  RCC_ClkInitStruct.APB4CLKDivider = RCC_APB4_DIV2;

  if (HAL_RCC_ClockConfig(&RCC_ClkInitStruct, FLASH_LATENCY_3) != HAL_OK)
  {
    Error_Handler();
  }
}

 /* MPU Configuration */

void MPU_Config(void)
{
  MPU_Region_InitTypeDef MPU_InitStruct = {0};

  /* Disables the MPU */
  HAL_MPU_Disable();

  /** Initializes and configures the Region and the memory to be protected
  */
  MPU_InitStruct.Enable = MPU_REGION_ENABLE;
  MPU_InitStruct.Number = MPU_REGION_NUMBER0;
  MPU_InitStruct.BaseAddress = 0x0;
  MPU_InitStruct.Size = MPU_REGION_SIZE_4GB;
  MPU_InitStruct.SubRegionDisable = 0x87;
  MPU_InitStruct.TypeExtField = MPU_TEX_LEVEL0;
  MPU_InitStruct.AccessPermission = MPU_REGION_NO_ACCESS;
  MPU_InitStruct.DisableExec = MPU_INSTRUCTION_ACCESS_DISABLE;
  MPU_InitStruct.IsShareable = MPU_ACCESS_SHAREABLE;
  MPU_InitStruct.IsCacheable = MPU_ACCESS_NOT_CACHEABLE;
  MPU_InitStruct.IsBufferable = MPU_ACCESS_NOT_BUFFERABLE;

  HAL_MPU_ConfigRegion(&MPU_InitStruct);
  /* Enables the MPU */
  HAL_MPU_Enable(MPU_PRIVILEGED_DEFAULT);

}

void HAL_TIM_PeriodElapsedCallback(TIM_HandleTypeDef *htim)
{
  /* USER CODE BEGIN Callback 0 */
  uint32_t status_value;
  status_value = taskENTER_CRITICAL_FROM_ISR();

  /* USER CODE END Callback 0 */
  if (htim->Instance == TIM1)
  {
    HAL_IncTick();
  }
  /* USER CODE BEGIN Callback 1 */

  // TIM2定时累加时间，每1ms累加一次，单位为ms
  if (htim->Instance == TIM2)
  {
    timer_ms++;

    if(a1_send_request == 0) // 如果没有发送请求，则每10ms设置一次发送请求
    {
        a1_send_request = 1; // 设置发送请求标志位
    }
  }

  // TIM6定时发送数据控制m8010电机，0.5ms会发送一次，每次发送一个电机的数据，依次循环4个电机
  if (htim->Instance == TIM6)
  {
    //  switch(timer_a1_flag)
    //  {
    //  	case 0:{A1_Motor_Send_Data(&A1_debug_485_1[0], &huart1); break;}
    //  	case 1:{A1_Motor_Send_Data(&A1_debug_485_1[1], &huart1); break;}
    //   case 2:{A1_Motor_Send_Data(&A1_debug_485_2[0], &huart9); break;}
    //  	case 3:{A1_Motor_Send_Data(&A1_debug_485_2[1], &huart9); break;}
    //  }
    //  timer_a1_flag++;
    //  if (timer_a1_flag > 3)	timer_a1_flag = 0;

    m8010_485_timer_trigger(htim);

    // 必须要等 RTOS 初始化完毕，信号量句柄不为空才能 Give 信号量
    if (bisem_m8010Handle != NULL)
    {
      // 去掉 static，并确保每次进中断时初始化为 pdFALSE
      BaseType_t xHigherPriorityTaskWoken = pdFALSE;
      xSemaphoreGiveFromISR(bisem_m8010Handle, &xHigherPriorityTaskWoken);
      portYIELD_FROM_ISR(xHigherPriorityTaskWoken);
    }
  }
  // TIM7定时发送数据控制m3508电机，1ms会发送一次
  if (htim->Instance == TIM7)
  {

    FDCAN_Send_M3508(&hfdcan1, m3508_fdcan1);
    FDCAN_Send_M3508(&hfdcan2, m3508_fdcan2);
    FDCAN_Send_M3508(&hfdcan3, m3508_fdcan3);

  }
  taskEXIT_CRITICAL_FROM_ISR(status_value); // 退出临界段

  /* USER CODE END Callback 1 */
}

void Error_Handler(void)
{
  __disable_irq();
  while (1)
  {
  }
}

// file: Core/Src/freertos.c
/* USER CODE BEGIN Header */
/**
 ******************************************************************************
 * File Name          : freertos.c
 * Description        : Code for freertos applications
 ******************************************************************************
 * @attention
 *
 * Copyright (c) 2026 STMicroelectronics.
 * All rights reserved.
 *
 * This software is licensed under terms that can be found in the LICENSE file
 * in the root directory of this software component.
 * If no LICENSE file comes with this software, it is provided AS-IS.
 *
 ******************************************************************************
 */
/* USER CODE END Header */

#include "FreeRTOS.h"
#include "task.h"
#include "main.h"
#include "cmsis_os.h"

/* USER CODE BEGIN Includes */
#include "tim.h"
#include "own_lib.h"
#include "mycan.h"
#include "myuart.h"
#include "filter.h"
#include "observer.h"
#include "pid.h"
#include "m3508.h"
#include "vofa.h"
#include "ANO_TC.h"
#include "arm_math.h"
#include "robotic_arm.h"
#include "chassis.h"
#include "clamp.h"
#include "ht10a.h"
#include "hi14.h"
#include "trajectory.h"
#include "BT_customized.h"
#include "radar.h"
#include "MF_planner.h"
#include "go_m8010.h"
#include "lift.h"
#include "H7_F1_spi.h"
#include "ir_action.h"
//#include "Ana_keyboard.h"
#include "screen.h"
#include "keyboard.h"
/* USER CODE END Includes */

/* USER CODE BEGIN Variables */
float debug_test_time; // 用于测试的万能小变量

int32_t debug_flag; // 万能小变量
uint8_t debug_mbt_start;  // 调试用行为树启动变量
float debug_position;
uint8_t point_add = 0;           // 测试用：是否添加路径点的标志位
uint8_t point_add1 = 0;          // 测试用：是否添加路径点的标志位
uint8_t kalman_update_times = 0; // 卡尔曼滤波更新次数统计
uint8_t kalman_init_flag = 0;    // 卡尔曼滤波初始化flag

/* 自适应一阶低通滤波变量（与卡尔曼对照） */
// 静止时深滤波（alpha小），运动时浅滤波（alpha大），解决静止雷达抖动
#define LOWPASS_ALPHA_STATIC     0.05f   // 静止：截止频率≈0.3Hz，强去噪
#define LOWPASS_ALPHA_MOVING     0.9f     // 运动：截止频率≈16Hz，快速跟踪
#define LOWPASS_SPEED_THRESH     50.0f    // 线速度阈值
#define LOWPASS_ANGULAR_THRESH   50.0f     // 角速度阈值

float radar_x_lowpass = 0.0f;
float radar_y_lowpass = 0.0f;
float radar_z_lowpass = 0.0f;
uint8_t lowpass_init_flag = 0;   // 低通初始化标志

float vx, vy, vw = 0.0f;         // 用于测试的底盘速度变量
float speed = 0.0f;              // 用于测试的速度变量
uint8_t catch_flag = 0;          // 测试用：夹爪开合标志位
int32_t rotate_target_angle = 0; // 测试用：夹爪旋转目标角度
uint8_t task_flag = 0;           // A/B/C/D 主赛启动与断电重试入口
float debug_speed;               // 用于测试的速度变量
int16_t leidai_speed_1 = 300;    //由于雷达建图的低速
int16_t leidai_speed_2 = 1000;    //由于雷达建图的高速
uint8_t camera_send = 0;         //测试用：相机发送请求
float arm_target_x = 0.0f;        //测试用：机械臂轨迹点
float arm_target_y = 0.0f;
uint8_t arm_pump = 0;
uint8_t camera_command = 0;
float angle = 0.0f;
uint8_t traj_init_flag_arm = 0;     // 机械臂轨迹初始化标志位
uint8_t traj_init_flag_lift = 0;    // 抬升轨迹初始化标志位
uint8_t traj_init_flag_chassis = 0; // 底盘轨迹初始化标志位

extern volatile uint8_t a1_send_request;
static uint8_t c8_spi_poll_cnt = 0;
/* USER CODE END Variables */
osThreadId defaultTaskHandle;
osThreadId roboticarm_taskHandle;
osThreadId chassis_taskHandle;
osThreadId clamp_taskHandle;
osThreadId cmd_taskHandle;
osThreadId m8010_taskHandle;
osThreadId a1_taskHandle;
osSemaphoreId bisem_m8010Handle;
osStaticSemaphoreDef_t bisem_m8010ControlBlock;

/* USER CODE BEGIN FunctionPrototypes */
// #ifndef bisem_m8010Handle
//	osSemaphoreId bisem_m8010Handle;
// #endif
/* USER CODE END FunctionPrototypes */

void StartDefaultTask(void const * argument);
void entry_robotic_arm(void const * argument);
void entry_chassis(void const * argument);
void entry_clamp(void const * argument);
void entry_cmd_task(void const * argument);
void entry_m8010_task(void const * argument);
void entry_a1_task(void const * argument);

void MX_FREERTOS_Init(void); /* (MISRA C 2004 rule 8.1) */

/* GetIdleTaskMemory prototype (linked to static allocation support) */
void vApplicationGetIdleTaskMemory( StaticTask_t **ppxIdleTaskTCBBuffer, StackType_t **ppxIdleTaskStackBuffer, uint32_t *pulIdleTaskStackSize );

/* USER CODE BEGIN GET_IDLE_TASK_MEMORY */
static StaticTask_t xIdleTaskTCBBuffer;
static StackType_t xIdleStack[configMINIMAL_STACK_SIZE];

void vApplicationGetIdleTaskMemory(StaticTask_t **ppxIdleTaskTCBBuffer, StackType_t **ppxIdleTaskStackBuffer, uint32_t *pulIdleTaskStackSize)
{
  *ppxIdleTaskTCBBuffer = &xIdleTaskTCBBuffer;
  *ppxIdleTaskStackBuffer = &xIdleStack[0];
  *pulIdleTaskStackSize = configMINIMAL_STACK_SIZE;
  /* place for user code */
}
/* USER CODE END GET_IDLE_TASK_MEMORY */

void MX_FREERTOS_Init(void) {

  /* Create the semaphores(s) */
  /* definition and creation of bisem_m8010 */
  osSemaphoreStaticDef(bisem_m8010, &bisem_m8010ControlBlock);
  bisem_m8010Handle = osSemaphoreCreate(osSemaphore(bisem_m8010), 1);

  /* USER CODE BEGIN RTOS_SEMAPHORES */

  // CubeMX 创建的信号量默认计数为 1，需要先 take 掉让它变为 0
  osSemaphoreWait(bisem_m8010Handle, 0); // 非阻塞地取走初始的 1，使计数变为 0

  /* add semaphores, ... */
  /* USER CODE END RTOS_SEMAPHORES */

  /* Create the thread(s) */
  /* definition and creation of defaultTask */
  osThreadDef(defaultTask, StartDefaultTask, osPriorityIdle, 0, 256);
  defaultTaskHandle = osThreadCreate(osThread(defaultTask), NULL);

  /* definition and creation of roboticarm_task */
  osThreadDef(roboticarm_task, entry_robotic_arm, osPriorityBelowNormal, 0, 256);
  roboticarm_taskHandle = osThreadCreate(osThread(roboticarm_task), NULL);

  /* definition and creation of chassis_task */
  osThreadDef(chassis_task, entry_chassis, osPriorityBelowNormal, 0, 256);
  chassis_taskHandle = osThreadCreate(osThread(chassis_task), NULL);

  /* definition and creation of clamp_task */
  osThreadDef(clamp_task, entry_clamp, osPriorityBelowNormal, 0, 256);
  clamp_taskHandle = osThreadCreate(osThread(clamp_task), NULL);

  /* definition and creation of cmd_task */
  osThreadDef(cmd_task, entry_cmd_task, osPriorityNormal, 0, 1024);
  cmd_taskHandle = osThreadCreate(osThread(cmd_task), NULL);

  /* definition and creation of m8010_task */
  osThreadDef(m8010_task, entry_m8010_task, osPriorityNormal, 0, 128);
  m8010_taskHandle = osThreadCreate(osThread(m8010_task), NULL);

  /* definition and creation of a1_task */
  osThreadDef(a1_task, entry_a1_task, osPriorityNormal, 0, 128);
  a1_taskHandle = osThreadCreate(osThread(a1_task), NULL);

}

void StartDefaultTask(void const * argument)
{
  /* USER CODE BEGIN StartDefaultTask */

  // start tim2
  TIM2->CNT = 0;
  HAL_TIM_Base_Start_IT(&htim2);
  // start tim6
  TIM6->CNT = 0;
  HAL_TIM_Base_Start_IT(&htim6);
  // start tim7
  TIM7->CNT = 0;
  HAL_TIM_Base_Start_IT(&htim7);
/* Infinite loop */
  for (;;)
  {
    //=======================================================================
    // vofa显示调试信息

    // data_send_vofa[0] = arm.x0_now;
    // data_send_vofa[1] = arm_traj.traj_x.out_pos;
    // data_send_vofa[2] = arm_traj.traj_queue_x.points[arm_traj.traj_queue_x.tail > 0 ? arm_traj.traj_queue_x.tail - 1 : 0];
    // data_send_vofa[3] = arm.y0_now;
    // data_send_vofa[4] = arm_traj.traj_y.out_pos;
    // data_send_vofa[5] = arm_traj.traj_queue_y.points[arm_traj.traj_queue_y.tail > 0 ? arm_traj.traj_queue_y.tail - 1 : 0];
    // data_send_vofa[0] = Radar_Pos.reliable_yaw;
    // data_send_vofa[1] = chassis_route_traj.traj_vw.target_pos;
    // data_send_vofa[2] = Radar_Pos.reliable_x;
    // 此处measure.Pos是实际转子位置减去初始位置（即电机上电时的位置），加上初始位置的目的是为了显示实际的机械位置（相对于上电时的零点）
    // 因此此处将measure.pos加上init_pos显示的数值是电机的实际位置，更直观地和发给电机的位置环目标进行对比
    // data_send_vofa[0] =chassis_route_traj.traj_vx.out_pos ;
    // data_send_vofa[1] = Radar_Pos.reliable_x;
    // data_send_vofa[2] = chassis_route_traj.traj_vx.out_vel;
    // data_send_vofa[3] = chassis_route_traj.traj_vx.target_pos;
    // data_send_vofa[4] = Radar_Pos.radar_x;
    // data_send_vofa[5] = Radar_Pos.radar_x_filtered;
    // data_send_vofa[6] = m3508_fdcan3[0].Now_Speed;
    // data_send_vofa[7] = m3508_fdcan3[0].M3508_Speed_PID.Target;
    // Vofa 10通道：卡尔曼 vs 低通对比视图
    data_send_vofa[0] = Radar_Pos.radar_x;            // ch0: 雷达原始X
    data_send_vofa[1] = Radar_Pos.radar_x_filtered;   // ch1: 卡尔曼滤波X
    data_send_vofa[2] = radar_x_lowpass;              // ch2: 一阶低通X
    data_send_vofa[3] = Radar_Pos.reliable_x;         // ch3: 最终使用X
    // data_send_vofa[4] = chassis_route_traj.traj_vx.out_vel;          // ch4: 雷达原始Y
    // data_send_vofa[5] = Radar_Pos.radar_y_filtered;   // ch5: 卡尔曼滤波Y
    // data_send_vofa[6] = radar_y_lowpass;              // ch6: 一阶低通Y
    // data_send_vofa[7] = Radar_Pos.reliable_y;         // ch7: 最终使用Y
    // data_send_vofa[0] = m3508_fdcan3[0].M3508_Speed_PID.Target; // ch0: 目标速度
    // data_send_vofa[1] = m3508_fdcan3[0].Now_Speed;              // ch1: 实际速度
    // data_send_vofa[2] = m3508_fdcan3[1].M3508_Speed_PID.Target; // ch2: 目标速度
    // data_send_vofa[3] = m3508_fdcan3[1].Now_Speed;              // ch3: 实际速度
    // data_send_vofa[4] = m3508_fdcan3[2].M3508_Speed_PID.Target; // ch4: 目标速度
    // data_send_vofa[5] = m3508_fdcan3[2].Now_Speed;              // ch5: 实际速度
    // data_send_vofa[6] = m3508_fdcan3[3].M3508_Speed_PID.Target; // ch6: 目标速度
    // data_send_vofa[7] = m3508_fdcan3[3].Now_Speed;              // ch7: 实际速度

    // vofa_send_to_show_justfloat(&huart7, data_send_vofa);
    // vofa显示调试信息
    //=======================================================================

    // UART7 is now used by screen.c; do not send VOFA on the same port.
    /*
     * H7 通过 SPI1 轮询 F103C8T6 的红外接收结果，并交给 ir_action 处理。
     * IR_Action_Poll() 内部会调用 H7_F1_SPI_Task()：
     *   1. 有新红外帧时，更新 h7_f1_spi_last_frame 和 ir_action_rx_frame；
     *   2. 如果红外帧匹配指定数据包，则置位 MC_bb.DOCKING_SUCCESS = 1；
     *   3. 没有新红外帧时，显示用的数据包会清零，方便 Watch 观察。
     * 调试时可观察：
     *   h7_f1_spi_rx_ok_count / h7_f1_spi_last_ch / h7_f1_spi_last_frame
     *   ir_action_rx_count / ir_action_rx_frame / ir_action_docking_success_set_count
     */
//    c8_spi_poll_cnt++;
//    if (c8_spi_poll_cnt >= 5U)
//    {
//      c8_spi_poll_cnt = 0;
      IR_Action_Poll();
//    }

    debug_test_time += 0.001f;
		// Screen_TestDisplay();
    osDelay(10); // 100Hz
  }
  /* USER CODE END StartDefaultTask */
}

void entry_robotic_arm(void const * argument)
{
  /* USER CODE BEGIN entry_robotic_arm */

  // 机械臂dh参数初始化
  arm_joint_parameter_init(&arm);

  // 机械臂上的3508参数初始化
   m3508_parameter_init(&m3508_fdcan1[0], 2.0f, 0.0f, 2.0f, 4.5f, 0.0f, 25.0f);
  // m3508_parameter_init(&m3508_fdcan1[0], 0.0f, 0.0f, 0.0f, 0.0f, 0.0f, 0.0f);

  // 末端执行器默认目标姿态
  arm.effector_pitch_target = 0.0f;
  // arm.theta_target[4] = 0.0f;

  // 初始化机械臂工作区域
  arm.mode = ARM_MODE_FRONT;
  /* Infinite loop */
  for (;;)
  {
    arm_joint_state_update(&arm);
    arm_route_point_calculate_front(&arm);

  /* 调试相关代码，实际使用需要被注释掉 */
    // if(debug_flag == 1){
    //   debug_flag = 0;
    //   arm_mode_switch_to_transition(&arm, &arm_traj, &arm_trans_traj, ARM_TRANS_FRONT_TO_BACK);
    // }
    // if(debug_flag == 2){
    //   debug_flag = 0;
    //   arm_mode_switch_to_transition(&arm, &arm_traj, &arm_trans_traj, ARM_TRANS_BACK_TO_FRONT);
    // }
    // if(debug_flag == 3){
    //   debug_flag = 0;
    //   arm_queue_add_point(&arm_traj, 0.4, 0.4, 0.0f, 500, 0);
    // }
    // if(debug_flag == 4){
    //   debug_flag = 0;
    //   arm_queue_add_point(&arm_traj, 0.5, 0.5, 0.0f, 500, 0);
    // }
    // if(debug_flag == 5){
    //   debug_flag = 0;
    //   arm_queue_add_point(&arm_traj, -0.4, 0.4, 0.0f, 500, 0);
    // }
    // if(debug_flag == 6){
    //   debug_flag = 0;
    //   arm_queue_add_point(&arm_traj, -0.5, 0.5, 0.0f, 500, 0);
    // }

    // 等待初始化完成
    if(A1_debug_485_2[0].Pos_init_flag == 200
      && m8010_bus_1.motors[2].measure.Pos_init_flag == 200
      && m3508_fdcan1[0].Initial_flag == 200)
    {
      if (traj_init_flag_arm == 0)
      {
        arm_trajectory_init(&arm_traj, &arm);   // 以当前位置初始化轨迹系统
        arm_queue_add_point(&arm_traj, PICK_PRE_REST_X, PICK_PRE_REST_Y, 200, ARM_PUMP_SUCK, 0.0f);
        arm_queue_add_point(&arm_traj, PICK_REST_X, PICK_REST_Y, 500, ARM_PUMP_SUCK, 0.0f);
        traj_init_flag_arm = 1;
      }
//       if(point_add == 1)
//       {
//         arm_queue_add_point(&arm_traj,arm_target_x,arm_target_y,0,0,arm_pump,angle * PI /180.0f);
//         point_add=0;
//       }
      // if(point_add == 2)
      //  {
      //    arm_queue_add_point(&arm_traj,PICK_REST_X,PICK_REST_Y,0,0,1);
      //    point_add=0;
      //  }
			//   if(point_add == 3)
      //  {
      //    arm_queue_add_point(&arm_traj,PICK_REST_X,PICK_REST_Y,0,0,2);
      //    point_add=0;
      //  }
      //  if(point_add == 1)
      // {
      //   arm_queue_add_point(&arm_traj,arm_target_x,arm_target_y,0,0,arm_pump);
      //   arm.effector_pitch_target = angle * 3.14f /180.0f;
      //   point_add=0;
      // }
      // if(point_add == 2)
      //  {
      //    arm_queue_add_point(&arm_traj,PICK_REST_X,PICK_REST_Y,0,0,1);
      //    point_add=0;
      //  }
			//   if(point_add == 3)
      //  {
      //    arm_queue_add_point(&arm_traj,PICK_REST_X,PICK_REST_Y,0,0,2);
      //    point_add=0;
      //  }
			// if(point_add == 4)
      // {
      //   arm_queue_add_point(&arm_traj,0.1f,1.0f,0,0,0);
			// 	arm_queue_add_point(&arm_traj,0.2f,1.0f,0,500,0);
      //   point_add=0;
      // }
      // 保持执行器水平
      // if (m3508_fdcan1[0].Initial_flag == 200 && arm.mode != ARM_MODE_TRANSITION)
      // {
      //   arm_actuator_stable_control(&arm, arm.effector_pitch_target, arm.theta_target[4]);
      // }

      // 1. 调用多段直线插补协调器 (它会从队列中成组提取路点)
      arm_linear_interpolation_update(&arm, &arm_traj, 0.05f);

      // 2. 分别推演 X 和 Y 的单段物理影子 (0.001f 代表 1ms)
      Traj_Adaptive_Update(&arm_traj.traj_x, arm.x0_now, 0.001f);
      Traj_Adaptive_Update(&arm_traj.traj_y, arm.y0_now, 0.001f);
      // Traj_Adaptive_Update(&arm_traj.traj_w, m8010_bus_1.motors[0].measure.Pos, 0.001f);

      // 3. 将影子坐标交接给逆解器（当工作区不处于过渡模式时）
      if (arm.mode == ARM_MODE_FRONT || arm.mode == ARM_MODE_BACK)
      {
        arm.x0_target = arm_traj.traj_x.out_pos;
        arm.y0_target = arm_traj.traj_y.out_pos;
        // arm.theta_target[0] = arm_traj.traj_w.out_pos;
      }

      //       // 4. 开始逆向解算出各个 theta_target，并转换成电机位置环
      //       arm_route_point_calculate(&arm);
      // //      arm_route_execute(&arm, 3.5f, 0.35f); // 位置环控制
      //       arm_route_execute(&arm, 0.0f, 0.0f, 0.0f, 0.0f);  // 不控制
      //       // arm_gravity_comp(); // 重力补偿

      // 4. 逆解算出各关节的 theta_target ，并转换成电机位置环
      arm_mode_update_execute(&arm, &arm_traj, &arm_trans_traj, 8.0f, 0.25f, 0.3f, 3.5f); // 位置环控制
      // arm_mode_update_execute(&arm, &arm_traj, &arm_trans_traj, 0.0f, 0.0f, 0.0f, 0.0f);

    }
    osDelay(1);
  }
  /* USER CODE END entry_robotic_arm */
}

void entry_chassis(void const * argument)
{
  /* USER CODE BEGIN entry_chassis */
  // 3508参数初始化（速度环 + 位置环）
  m3508_parameter_init(&m3508_fdcan3[0], 15.0f, 0.00f, 3.0f, 0.1f, 0.0f, 0.2f);
  m3508_parameter_init(&m3508_fdcan3[1], 15.0f, 0.00f, 3.0f, 0.1f, 0.0f, 0.2f);
  m3508_parameter_init(&m3508_fdcan3[2], 15.0f, 0.00f, 3.0f, 0.1f, 0.0f, 0.2f);
  m3508_parameter_init(&m3508_fdcan3[3], 15.0f, 0.00f, 3.0f, 0.1f, 0.0f, 0.2f);
  // 底盘使能
  chassis_r2.chassis_en_flag = 1;

  // 抬升机构辅助轮电机初始化
  m3508_parameter_init(&m3508_fdcan1[1], 0.0f, 0.0f, 0.0f, 0.0f, 0.0f, 0.0f);
  m3508_parameter_init(&m3508_fdcan1[2], 0.0f, 0.0f, 0.0f, 0.0f, 0.0f, 0.0f);
  // 底盘升降初始化为收回状态
  // chassis_r2.lift_front = 0;
  // chassis_r2.lift_back = 0;
  // chassis_lift_front_control(chassis_r2.lift_front);
  // chassis_lift_back_control(chassis_r2.lift_back);
  // chassis_route_traj_init();

  /* Infinite loop */
  for (;;)
  {
    if (m3508_fdcan3[0].Initial_flag == 200 && m3508_fdcan3[1].Initial_flag == 200 && m3508_fdcan3[2].Initial_flag == 200 && m3508_fdcan3[3].Initial_flag == 200)
    {
     // DR_Update();
      // //雷达建图用
      // if (HT10A.switch_d == -1)
      // {
      //   if (HT10A.left_y > 0)chassis_r2.vx = leidai_speed_1;
      //   else if (HT10A.left_y < 0)chassis_r2.vx = -leidai_speed_1;
      //   else if(HT10A.left_y == 0)chassis_r2.vx = 0;
      //   if (HT10A.left_x > 0)chassis_r2.vy = -leidai_speed_1;
      //   else if (HT10A.left_x < 0)chassis_r2.vy = leidai_speed_1;
      //   else if(HT10A.left_x == 0)chassis_r2.vy = 0;
      //    if (HT10A.right_y > 0)chassis_r2.vw = leidai_speed_1;
      //   else if (HT10A.right_y < 0)chassis_r2.vw = -leidai_speed_1;
      //   else if(HT10A.right_y == 0)chassis_r2.vw = 0;
      // }
      // if (HT10A.switch_d == 1)
      // {
      //   if (HT10A.left_y > 0)chassis_r2.vx = leidai_speed_2;
      //   else if (HT10A.left_y < 0)chassis_r2.vx = -leidai_speed_2;
      //   else if(HT10A.left_y == 0)chassis_r2.vx = 0;
      //   if (HT10A.left_x > 0)chassis_r2.vy = -leidai_speed_2;
      //   else if (HT10A.left_x < 0)chassis_r2.vy = leidai_speed_2;
      //    else if(HT10A.left_x == 0)chassis_r2.vy = 0;
      //    if (HT10A.right_y > 0)chassis_r2.vw = leidai_speed_2;
      //   else if (HT10A.right_y < 0)chassis_r2.vw = -leidai_speed_2;
      //   else if(HT10A.right_y == 0)chassis_r2.vw = 0;
      // }
      //一区平移测试
      // if (point_add== 1 )
      //  {
      //    chassis_route_point_add(&chassis_route_traj,1000.0f,-1400.0f,0.0f,0,0);
			//  	point_add = 0;
      //  }
      //  if (point_add== 2 )
      //  {
      //    chassis_route_point_add(&chassis_route_traj,2000.0f,-1400.0f,180.0f,0,0);
			//  	point_add = 0;
      //  }
    //  //测试用添加路径点
//     if (point_add == 1)
//     {
//       chassis_route_point_add(&chassis_route_traj, R_CHASSIS_CZ_INIT_X, R_CHASSIS_CZ_INIT_Y, R_CHASSIS_CZ_INIT_W, 0);
//       point_add = 0;
//     }
//     if (point_add == 2)
//     {
//       chassis_route_point_add(&chassis_route_traj, R_CHASSIS_SUDUKU_1_X, R_CHASSIS_SUDUKU_1_Y, R_CHASSIS_SUDUKU_1_W, 0);
//       point_add = 0;
//     }
//     if (point_add == 3)
//     {
//       chassis_route_point_add(&chassis_route_traj, R_CHASSIS_SUDUKU_2_X, R_CHASSIS_SUDUKU_2_Y, R_CHASSIS_SUDUKU_2_W, 0);
//       point_add = 0;
//     }
//     if (point_add == 4)
//     {
//       chassis_route_point_add(&chassis_route_traj, R_CHASSIS_SUDUKU_3_X, R_CHASSIS_SUDUKU_3_Y, R_CHASSIS_SUDUKU_3_W, 0);
//       point_add = 0;
//     }
//
//     if (point_add1 == 1)
//     {
//       chassis_route_point_add(&chassis_route_traj, 11100.0f, -3000.0f, 90.0f, 0);
//       point_add1 = 0;
//     }
    //上坡测试
//     if (point_add == 1)
//     {
//       chassis_route_point_add(&chassis_route_traj, R_CHASSIS_SLOPE_START_X, R_CHASSIS_SLOPE_START_Y, R_CHASSIS_SLOPE_START_W, 0);
//       point_add = 0;
//     }
//     if (point_add == 2)
//     {
//       chassis_route_point_add(&chassis_route_traj, R_CHASSIS_CZ_INIT_X, R_CHASSIS_CZ_INIT_Y, 0, 0);
//       point_add = 0;
//     }
// if (point_add == 1)
//      {
//        chassis_route_point_add(&chassis_route_traj, 11500,-4000.0f, 0.0f, 0);
//        point_add = 0;
//      }
//      if (point_add == 2)
//      {
//        chassis_route_point_add(&chassis_route_traj, 11100,-2400.0f, 180.0f, 0);
//        point_add = 0;
//      }
    //  if (point_add == 1)
    //   {
    //     chassis_route_point_add(&chassis_route_traj, 11080,-3055.0f, 90.0f, 0);
    //     point_add = 0;
    //   }
    //三区点位
//    if (point_add == 1)
//      {
//        chassis_route_point_add(&chassis_route_traj, R_CHASSIS_SLOPE_END_X,R_CHASSIS_SLOPE_END_Y, 90.0f, 0,0);
//        point_add = 0;
//      }
//    if (point_add == 2)
//      {
//        chassis_route_point_add(&chassis_route_traj,R_CHASSIS_CZ_CENTER_X,R_CHASSIS_CZ_CENTER_Y, R_CHASSIS_CZ_CENTER_W, 0,0);
//        point_add = 0;
//      }if (point_add == 3)
//      {
//        chassis_route_point_add(&chassis_route_traj, R_CHASSIS_SUDUKU_1_X,R_CHASSIS_SUDUKU_1_Y, R_CHASSIS_SUDUKU_1_W, 0,0);
//        point_add = 0;
//      }
//      if (point_add == 4)
//      {
//        chassis_route_point_add(&chassis_route_traj, R_CHASSIS_SUDUKU_1_X,R_CHASSIS_SUDUKU_1_Y+500.0f, R_CHASSIS_SUDUKU_1_W, 0,0);
//        point_add = 0;
//      }
//if(point_add == 1)
//{
//  chassis_route_point_add(&chassis_route_traj, 11400.0f,-2000.0f, 0.0f, 0,0);
//  chassis_route_point_add(&chassis_route_traj, 11400.0f,-1500.0f, -90.0f, 0,0);
//  chassis_route_point_add(&chassis_route_traj, 11400.0f,-2500.0f, 90.0f, 0,1);
//	chassis_route_point_add(&chassis_route_traj, 11400.0f,-1500.0f, -90.0f, 0,0);
//  point_add = 0;
//}
       if (point_add == 1)
      {
        chassis_route_point_add(&chassis_route_traj,arm_target_x,arm_target_y, angle, 0,0);
        point_add = 0;
      }

      // // 滤波后的雷达数据更新
      Radar_Pos.radar_x_filtered = Kalman_Update(&Radar_Kalman_X, Radar_Pos.radar_x);
      Radar_Pos.radar_y_filtered = Kalman_Update(&Radar_Kalman_Y, Radar_Pos.radar_y);
      Radar_Pos.radar_z_filtered = Kalman_Update(&Radar_Kalman_Z, Radar_Pos.radar_z);

      // 一阶低通滤波（与卡尔曼对照）
      if (lowpass_init_flag == 0)
      {
          radar_x_lowpass = Radar_Pos.radar_x;
          radar_y_lowpass = Radar_Pos.radar_y;
          radar_z_lowpass = Radar_Pos.radar_z;
          lowpass_init_flag = 1;
      }

      // 利用电机速度计算底盘实际速度（逆解算）
      omni_chassis_inverse_calculate(&chassis_r2, m3508_fdcan3);

      // 自适应 alpha + 速度前馈预测：静止时深滤波去抖，运动时预测+浅滤波消滞后
      {
          float linear_speed = sqrtf(chassis_r2.real_vx * chassis_r2.real_vx + chassis_r2.real_vy * chassis_r2.real_vy);
          uint8_t is_static = (linear_speed < LOWPASS_SPEED_THRESH) && (abs_float(chassis_r2.real_vw) < LOWPASS_ANGULAR_THRESH);
          float alpha = is_static ? LOWPASS_ALPHA_STATIC : LOWPASS_ALPHA_MOVING;

          if (!is_static)
          {
              // 仅运动时做速度前馈预测（dt=0.001s），静止跳过防止电机速度毛刺注入
              radar_x_lowpass += chassis_r2.real_vx * 0.001f;
              radar_y_lowpass += chassis_r2.real_vy * 0.001f;
          }
          // 测量修正：雷达观测值拉回预测误差
          radar_x_lowpass += alpha * (Radar_Pos.radar_x - radar_x_lowpass);
          radar_y_lowpass += alpha * (Radar_Pos.radar_y - radar_y_lowpass);
          radar_z_lowpass += alpha * (Radar_Pos.radar_z - radar_z_lowpass);
      }

      // 输出可靠位置：静止死区锁定防抖，运动速度前馈无滞后
      {
          float linear_speed = sqrtf(chassis_r2.real_vx * chassis_r2.real_vx + chassis_r2.real_vy * chassis_r2.real_vy);
          uint8_t is_static = (linear_speed < LOWPASS_SPEED_THRESH) && (abs_float(chassis_r2.real_vw) < LOWPASS_ANGULAR_THRESH);

          // 静止且 X/Y 都在死区内 → 锁定，不更新（抑制震荡）
          if (is_static
              && abs_float(radar_x_lowpass - Radar_Pos.reliable_x) < POS_HOLD_DEADBAND
              && abs_float(radar_y_lowpass - Radar_Pos.reliable_y) < POS_HOLD_DEADBAND)
          {
              ;// 真正锁定：什么都不做，维持上次 reliable 值
          }
          else
          {
              Radar_Pos.reliable_x = radar_x_lowpass;
              Radar_Pos.reliable_y = radar_y_lowpass;
              Radar_Pos.reliable_z = radar_z_lowpass;
          }
          Radar_Pos.reliable_yaw = Radar_Pos.hi14_yaw;
      }

//					 Radar_Pos.reliable_x = Radar_Pos.radar_x;
//           Radar_Pos.reliable_y = Radar_Pos.radar_y;
//           Radar_Pos.reliable_yaw = Radar_Pos.hi14_yaw;

      if (traj_init_flag_chassis == 0)
      {
        // 以当前坐标初始化底盘路径系统
        chassis_route_traj_init();
        traj_init_flag_chassis = 1;
      }

      // 多段-单段-坐标系变换-底盘解算 路径执行部分
      if (traj_init_flag_chassis == 1)
      {
        chassis_multi_route_scheduler(&chassis_route_traj, &Radar_Pos);
        chassis_single_route_scheduler(&Radar_Pos, &chassis_route_traj, 1);
        chassis_world_to_robot_velocity(&chassis_r2, chassis_route_traj.traj_vx.out_vel, chassis_route_traj.traj_vy.out_vel, chassis_route_traj.traj_vw.out_vel, Radar_Pos.reliable_yaw);
        if (chassis_r2.chassis_lock_flag)
          chassis_position_lock_execute();   /* 位置环锁止：死守捕获编码器位置 */
        else
          omni_chassis_calculate(&chassis_r2, chassis_r2.vx, chassis_r2.vy, chassis_r2.vw, chassis_r2.chassis_en_flag);
      }
      }

    /* ========================= 抬升部分 ========================= */

    if (m8010_bus_3.motors[0].measure.Pos_init_flag == 200 && m8010_bus_3.motors[1].measure.Pos_init_flag == 200)
    {
      // 1. 正向运动学更新当前升降高度
      chassis_lift_fk_update(&chassis_r2);
      if (traj_init_flag_lift == 0)
      {
        // 以当前升降高度初始化升降轨迹系统
        chassis_lift_traj_init();
        // 添加一个默认的升降目标点，作为上电复位
        chassis_lift_queue_add_point(&chassis_lift_traj, LIFT_RETRACT_HEIGHT, LIFT_RETRACT_HEIGHT, 0);
        traj_init_flag_lift = 1;
      }
      // 2. 多段路径调度器：当前段完成→从队列出队下一个目标
      chassis_lift_linear_interpolation_update(&chassis_r2, &chassis_lift_traj, CHASSIS_LIFT_QUEUE_BLEND_RADIUS);
      // 3. 单段轨迹推演（影子位置 + 速度 + 自动判敛）
      Traj_Adaptive_Update(&chassis_lift_traj.traj_front, chassis_r2.lift_front_current, 0.001f);
      Traj_Adaptive_Update(&chassis_lift_traj.traj_back, chassis_r2.lift_back_current, 0.001f);
      // 4. 影子位置 → 目标高度
      chassis_r2.lift_front_target = chassis_lift_traj.traj_front.out_pos;
      chassis_r2.lift_back_target = chassis_lift_traj.traj_back.out_pos;
      // 5. 逆运动学：目标高度 → 电机位置
      chassis_lift_ik_update(&chassis_r2);
      // 6. 位置环执行
      // chassis_lift_excute(&chassis_r2, 2.0f, 0.2f);
      // chassis_lift_excute(&chassis_r2, 0.0f, 0.0f);
      // 7. 抬升轮速度执行
      // chassis_lift_wheel_excute(debug_speed, 2.0f, 0.2f);
      // chassis_lift_wheel_excute(debug_speed, 0.0f, 0.0f);

      // if(debug_flag == 1)
      // {
      //   debug_flag = 0;
      //   chassis_lift_queue_add_point(&chassis_lift_traj, -0.200f, -0.200f, 0);
      // }
      // if(debug_flag == 2)
      // {
      //   debug_flag = 0;
      //   chassis_lift_queue_add_point(&chassis_lift_traj, -0.400f, -0.400f, 0);
      // }
      // if(debug_flag == 3)
      // {
      //   debug_flag = 0;
      //   chassis_lift_queue_add_point(&chassis_lift_traj, LIFT_RETRACT_HEIGHT, LIFT_RETRACT_HEIGHT, 0);
      // }

      // 根据 lift FSM 设置的控制模式执行
      switch (g_lift_ctrl_mode) {
        case LIFT_CTRL_NONE:
        case LIFT_CTRL_POSITION:
            chassis_lift_excute(STEP_UP_BRACE_KP, STEP_UP_BRACE_KD, 1, 1);
            break;
        case LIFT_CTRL_FORCE_FRONT_REAR:
            m8010_torque_control(&m8010_bus_3.motors[0], g_lift_front_torque);
            m8010_torque_control(&m8010_bus_3.motors[1], g_lift_rear_torque);
            break;
        case LIFT_CTRL_FORCE_REAR_ONLY:
            chassis_lift_excute(STEP_UP_BRACE_KP, STEP_UP_BRACE_KD, 1, 0);
            m8010_torque_control(&m8010_bus_3.motors[1], -g_lift_rear_torque);
            break;
      }
      // switch (g_lift_ctrl_mode) {
      //   case LIFT_CTRL_NONE:
      //   case LIFT_CTRL_POSITION:
      //       chassis_lift_excute(&chassis_r2, 0.0f, 0.0f);
      //       break;
      //   case LIFT_CTRL_FORCE_FRONT_REAR:
      //       m8010_torque_control(&m8010_bus_3.motors[0], 0);
      //       m8010_torque_control(&m8010_bus_3.motors[1], 0);
      //       break;
      //   case LIFT_CTRL_FORCE_REAR_ONLY:
      //       chassis_lift_excute(&chassis_r2, 0.0f, 0.0f);
      //       m8010_torque_control(&m8010_bus_3.motors[1], 0);
      //       break;
      // }

      // 辅助轮执行
      chassis_lift_wheel_excute(g_lift_wheel_target, g_lift_wheel_kp, g_lift_wheel_kd);

    }

    osDelay(1);
  }
  /* USER CODE END entry_chassis */
}

void entry_clamp(void const * argument)
{
  /* USER CODE BEGIN entry_clamp */

  // 夹爪电机初始化
  m3508_parameter_init(&m3508_fdcan2[0], 10.0f, 0.0f, 2.0f, 0.5f, 0.0f, 0.2f);
  m3508_parameter_init(&m3508_fdcan2[1], 6.0f, 0.0f, 2.0f, 0.5f, 0.0f, 0.2f);
  m3508_parameter_init(&m3508_fdcan2[2], 5.0f, 0.0f, 2.0f, 0.5f, 0.0f, 0.2f);
  // m3508_parameter_init(&m3508_fdcan2[0], 0.0f, 0.0f, 0.0f, 0.0f, 0.0f, 0.0f);
  // m3508_parameter_init(&m3508_fdcan2[1], 0.0f, 0.0f, 0.0f, 0.0f, 0.0f, 0.0f);
  // m3508_parameter_init(&m3508_fdcan2[2], 0.0f, 0.0f, 0.0f, 0.0f, 0.0f, 0.0f);

  // 标志位初始化
  clamp.catch_flag = 0;
  clamp.rotate_flag = 0;
  clamp.retractable_flag = 0;
  clamp.lift_flag = 0;

  /* Infinite loop */
  for (;;)
  {
    if (m3508_fdcan2[0].Initial_flag == 200 && m3508_fdcan2[1].Initial_flag == 200 && m3508_fdcan2[2].Initial_flag == 200)
    {

      // 气缸驱动夹爪部分
      clamp_open_control(clamp.catch_flag);
      // 夹爪旋转部分
      clamp_rotate_control(clamp.rotate_flag * CLAMP_ROTATE_MAX_POSITION, &m3508_fdcan2[2]);
      // 夹爪伸缩部分
     clamp_extend_control(clamp.retractable_flag * CLAMP_EXTEND_MAX_POSITION, &m3508_fdcan2[1]);
      // // 夹爪升降部分
     clamp_lift_control(clamp.lift_flag, &m3508_fdcan2[0]);
       //m3508_anglesum_control(&m3508_fdcan2[0],rotate_target_angle,8000);
    }
    osDelay(1);
  }
  /* USER CODE END entry_clamp */
}

void entry_cmd_task(void const * argument)
{
  /* USER CODE BEGIN entry_cmd_task */

  BT_MASTER_Init_Task();
  mf_planner_ctx.map_color = BLUE_MAP;

  // task_flag = 1;

  /* Infinite loop */
  for (;;)
  {
//     if(camera_send == 1)
//     {
//       camera_send = 0;
//       MF_Scan_Command_Send(camera_command);
// //			MF_Scan_Command_Send(camera_command);
//     }

  /* 当按下按键时，根据最新地图刷新屏幕 */
  if(key_now != 0)
  {
    uint8_t screen_index = 0;

    if (Keyboard_MF_KeyToCell(key_now, NULL, NULL, &screen_index))
    {
      Merlin_SetBlock(screen_index, keyboard_kfs_screen_info[screen_index]);
    }
  }
  /* 按键启动部分 */
  if (key_now == 'A')
  {
    task_flag = 1;
    key_now = 0;
    key_last = 0;
  }
  else if (key_now == 'B')
  {
    task_flag = 2;
    key_now = 0;
    key_last = 0;
  }
  else if (key_now == 'C')
  {
    task_flag = 3;
    key_now = 0;
    key_last = 0;
  }
  else if (key_now == 'D')
  {
    task_flag = 4;
    key_now = 0;
    key_last = 0;
  }

  /* 按键-雷达偏移部分 */
  if(key_2_now == 1)
  {
    x_offset_by_key_times += 1;
    key_2_now = 0;
    key_2_last = 0;
  }
  else if(key_2_now == 5)
  {
    x_offset_by_key_times -= 1;
    key_2_now = 0;
    key_2_last = 0;
  }
  else if(key_2_now == 9)
  {
    y_offset_by_key_times += 1;
    key_2_now = 0;
    key_2_last = 0;
  }
  else if(key_2_now == 13)
  {
    y_offset_by_key_times -= 1;
    key_2_now = 0;
    key_2_last = 0;
  }

  /* 主赛重试入口：A=MC/全流程，B=MF，C=CZ存一拿一，D=CZ只拿一块。 */

  if (task_flag != 0)
  {
    /* 所有入口均汇入同一个 MASTER，运行期间忽略新的重启键。 */
    if (task_flag == 1 && !BT_MASTER_IsRunning())
    {
      /* A：全流程启动 / MC 区断电重试，只取一个端头。 */
      BT_MASTER_Start_Task();
    }
    else if (task_flag == 2)
    {
      /*
       * B：MC 已回重试区并等待 MF 时，放行进入 MF；
       * MASTER 已停止（例如 MF 失败清理后）时，从 MF 区重新开始。
       */
      if (!BT_MASTER_Request_MF_Start() && !BT_MASTER_IsRunning())
        BT_MASTER_Start_FromMF();
    }
    else if (task_flag == 3 && !BT_MASTER_IsRunning())
    {
      /* C：CZ 重试，车身存一块且机械臂持一块。 */
      BT_MASTER_Start_FromCZ(1U, 1U);
    }
    else if (task_flag == 4)
    {
      /* D 在 MC 等待态用于放行 MF；空闲时用于 CZ 无存块重试。 */
      if (!BT_MASTER_Request_MF_Start() && !BT_MASTER_IsRunning())
        BT_MASTER_Start_FromCZ(0U, 1U);
    }

    task_flag = 0;
  }
    // if(debug_flag == 1)
    // {
    //   debug_flag = 0;
    //   MF_Scan_Command_Send(1);
    // }
    // if(debug_flag == 2)
    // {
    //   debug_flag = 0;
    //   MF_Scan_Command_Send(2);
    // }
    // if(debug_flag == 3)
    // {
    //   debug_flag = 0;
    //   MF_Scan_Command_Send(3);
    // }

    BT_MASTER_Tick(); /* 1ms 调用，内部降频到 10ms，串行推进 MC -> MF -> CZ。 */
    osDelay(1);
  }
  /* USER CODE END entry_cmd_task */
}

void entry_m8010_task(void const * argument)
{
  /* USER CODE BEGIN entry_m8010_task */

  m8010_bus_1.motors[0].target.id = 1;
  m8010_bus_1.motors[0].target.mode = 1;
  m8010_bus_1.motors[1].target.id = 2;
  m8010_bus_1.motors[1].target.mode = 1;
  m8010_bus_1.motors[2].target.id = 3;
  m8010_bus_1.motors[2].target.mode = 1;

  m8010_bus_3.motors[0].target.id = 1;
  m8010_bus_3.motors[0].target.mode = 1;
  m8010_bus_3.motors[1].target.id = 2;
  m8010_bus_3.motors[1].target.mode = 1;
  // m8010_bus_3.motors[2].target.id = 3;
  // m8010_bus_3.motors[2].target.mode = 1;

  /* Infinite loop */
  for (;;)
  {
    osSemaphoreWait(bisem_m8010Handle, osWaitForever); // 等待信号量，确保在主循环中被正确触发

    m8010_bus_poll(&m8010_bus_1);
    // m8010_bus_poll(&m8010_bus_2);
    m8010_bus_poll(&m8010_bus_3);

    // osDelay(1);
  }
  /* USER CODE END entry_m8010_task */
}

void entry_a1_task(void const * argument)
{
  /* USER CODE BEGIN entry_a1_task */
  uint8_t timer_a1_flag = 0;
  /* Infinite loop */
  for(;;)
  {
    if (a1_send_request)
    {
      a1_send_request = 0;

      switch(timer_a1_flag)
      {
        case 0:
          A1_Motor_Send_Data(&A1_debug_485_2[0], &huart6);
          break;
        case 1:
          A1_Motor_Send_Data(&A1_debug_485_2[1], &huart6);
          break;
      }

      timer_a1_flag++;
      if (timer_a1_flag > 1) timer_a1_flag = 0;
    }

    osDelay(1);
  }
  /* USER CODE END entry_a1_task */
}
